# MDR1206AFI register map
Vendor: Milandr; File version: 1.0
CPU: BM-310S0, little endian
Registers are 32-bit, read-write, reset 0x0 unless marked. A register's access mark holds for its fields unless they carry their own. Offsets are from the block's base; [hi:lo] are bit positions; {n}, {i} and the like mark numbered series.

## PORTA — PORTA description
Base 0x50080000
Same registers: PORTB 0x50088000, PORTC 0x50090000, PORTD 0x500F0000
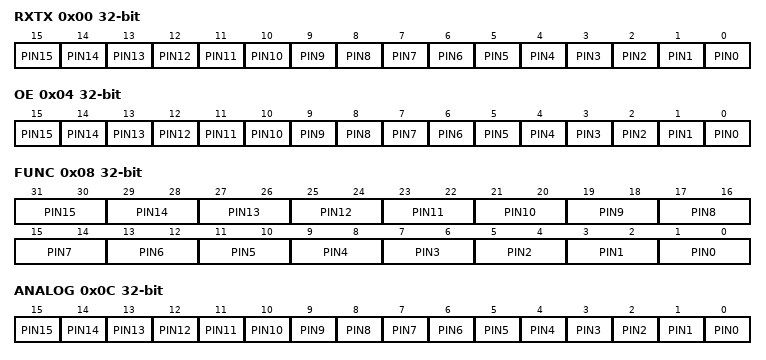
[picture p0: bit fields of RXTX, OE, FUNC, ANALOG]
0x00 RXTX — RXTX description
  [n] PIN{n} (n=0..15) — PIN{n} description
0x04 OE — OE description
  [n] PIN{n} (n=0..15) — PIN{n} description
0x08 FUNC — FUNC description
  [2n+1:2n] PIN{n} (n=0..15) — PIN{n} description
0x0C ANALOG — ANALOG description
  [n] PIN{n} (n=0..15) — PIN{n} description
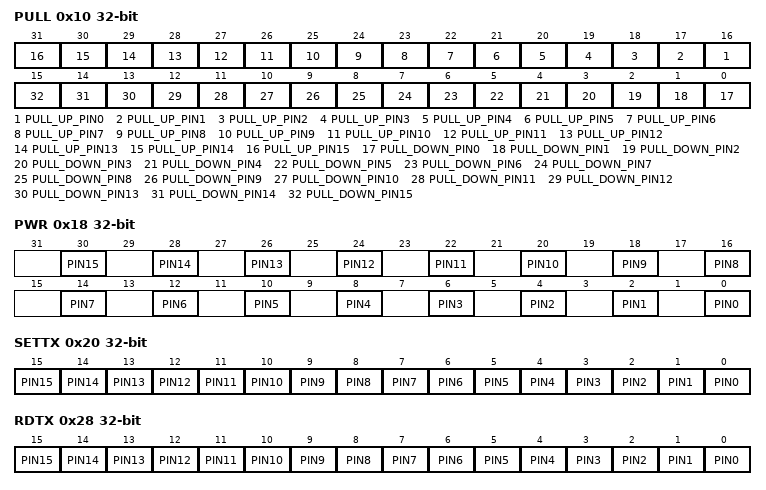
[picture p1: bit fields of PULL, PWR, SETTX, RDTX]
0x10 PULL — PULL description
  [n+16] PULL_UP_PIN{n} (n=0..15) — PULL_UP_PIN{n} description
  [n] PULL_DOWN_PIN{n} (n=0..15) — PULL_DOWN_PIN{n} description
0x18 PWR — PWR description
  [2n] PIN{n} (n=0..15) — PIN{n} description
0x20 SETTX — SETTX description
  [n] PIN{n} (n=0..15) — PIN{n} description
0x24 CLRTX — CLRTX description
0x28 RDTX ro — RDTX description
  [n] PIN{n} (n=0..15) — PIN{n} description

## CRC — CRC description
Base 0x50098000
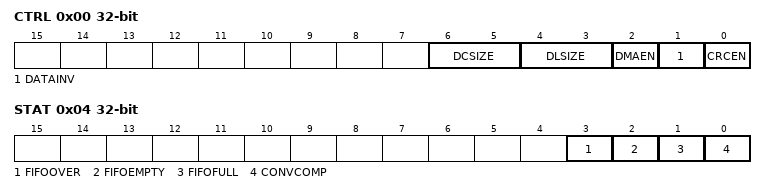
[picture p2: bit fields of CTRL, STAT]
0x00 CTRL — CTRL description
  [6:5] DCSIZE — DCSIZE description
  [4:3] DLSIZE — DLSIZE description
  [2] DMAEN — DMAEN description
  [1] DATAINV — DATAINV description
  [0] CRCEN — CRCEN description
0x04 STAT — STAT description
  [3] FIFOOVER — FIFOOVER description
  [2] FIFOEMPTY — FIFOEMPTY description
  [1] FIFOFULL — FIFOFULL description
  [0] CONVCOMP — CONVCOMP description
0x08 DATAI wo — DATAI description
  [31:0] DATA_IN — DATA_IN description
0x0C VAL — VAL description
  [15:0] CRCOUT — CRCOUT description
0x10 POL — POL description
  [16:0] CRC_POL — CRC_POL description

## RANDOM — RANDOM description
Base 0x500B8000
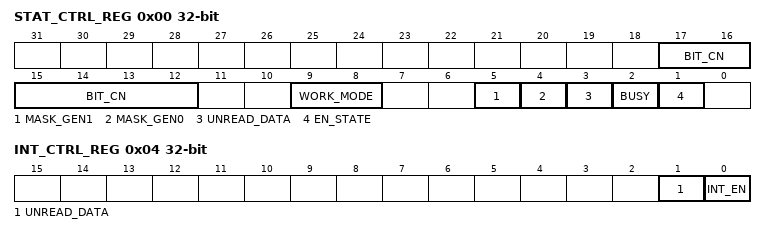
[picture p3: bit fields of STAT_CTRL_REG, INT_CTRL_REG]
0x00 STAT_CTRL_REG — Status and Control Register
  [17:12] BIT_CN ro — BIT_CN description
  [9:8] WORK_MODE — WORK_MODE description
  [5] MASK_GEN1 — MASK_GEN1 description
  [4] MASK_GEN0 — MASK_GEN0 description
  [3] UNREAD_DATA ro — UNREAD_DATA description
  [2] BUSY ro — BUSY description
  [1] EN_STATE ro — EN_STATE description
0x04 INT_CTRL_REG — Interrupt Control Register
  [1] UNREAD_DATA ro — UNREAD_DATA description
  [0] INT_EN — INT_EN description
0x08 CLK_DIV_REG — Clock Divider Register
  [15:0] DIV — DIV description
0x0C PAUSE_REG — Pause Register
0x10 OUTPUT_REG ro — Output Random Register
0x14 PAUSE_CNT_REG ro — Pause Counter Register
0x18 TEMP_REG ro — Temp Random Register

## USART — USART description
Base 0x500C0000
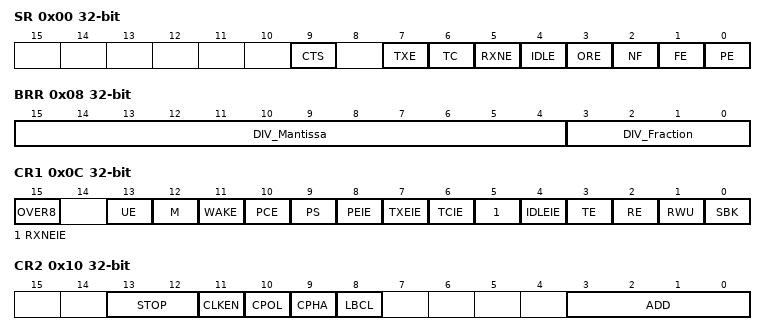
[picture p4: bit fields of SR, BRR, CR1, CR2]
0x00 SR — Status Register
  [9] CTS — CTS flag
  [7] TXE ro — TX empty
  [6] TC — Transmit complete
  [5] RXNE — Read data register not empty
  [4] IDLE ro — IDLE line detected
  [3] ORE ro — Overrun error
  [2] NF ro — Noise error flag
  [1] FE ro — Frame error
  [0] PE ro — Parity error
0x04 DR — Data Register
  [8:0] DR
0x08 BRR — Baud Rate Register
  [15:4] DIV_Mantissa, [3:0] DIV_Fraction
0x0C CR1 — Control Register 1
  [15] OVER8 — Oversampling mode
  [13] UE — USART Enable
  [12] M — Byte length. 1 - 9;0 - 8
  [11] WAKE — Wake bit
  [10] PCE — Parity control enable
  [9] PS — Parity selection
  [8] PEIE — PE interrupt enable
  [7] TXEIE — TXE interrupt enable
  [6] TCIE — Transmission complete interrupt enable
  [5] RXNEIE — RXNE interrupt enable
  [4] IDLEIE — IDLE interrupt enable
  [3] TE — Transmitter enable
  [2] RE — Receiver enable
  [1] RWU — Receiver wakeup
  [0] SBK — Send break
0x10 CR2 — Control Register 2
  [13:12] STOP — Stop bit type mask
  [11] CLKEN — Clock enable
  [10] CPOL — Clock polarity
  [9] CPHA — Clock phase
  [8] LBCL — Last bit clock pulse
  [3:0] ADD — Address of the USART node
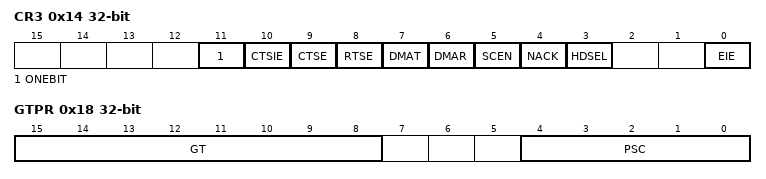
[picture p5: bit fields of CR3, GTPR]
0x14 CR3 — Control Register 3
  [11] ONEBIT — One sample per bit mode resolution
  [10] CTSIE — CTS interrupt enable
  [9] CTSE — CTS enable
  [8] RTSE — RTS enable
  [7] DMAT — DMA enable transmitter
  [6] DMAR — DMA enable receiver
  [5] SCEN — Smartcard mode enable
  [4] NACK — Smartcard NACK
  [3] HDSEL — Half-duplex selection
  [0] EIE — Error interrupt enable
0x18 GTPR — Guard Time and Prescaler Register
  [15:8] GT — GT description
  [4:0] PSC — PSC description
